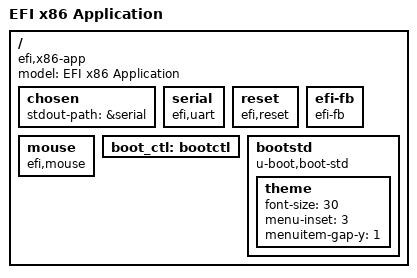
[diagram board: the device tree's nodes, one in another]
// SPDX-License-Identifier: GPL-2.0+
/*
 * Copyright (c) 2015 Google, Inc
 */

/dts-v1/;

/include/ "skeleton.dtsi"

#include "tsc_timer.dtsi"

/ {
	model = "EFI x86 Application";
	compatible = "efi,x86-app";

	chosen {
		stdout-path = &serial;
	};

	serial: serial {
		compatible = "efi,uart";
	};

	reset {
		compatible = "efi,reset";
		bootph-all;
	};
	efi-fb {
		compatible = "efi-fb";
		bootph-some-ram;
	};

	mouse {
		compatible = "efi,mouse";
	};

	boot_ctl: bootctl {
	};

	bootstd {
		compatible = "u-boot,boot-std";
		theme {
			font-size = <30>;
			menu-inset = <3>;
			menuitem-gap-y = <1>;
		};
	};

};

#include "bootctl.dtsi"
